# apollo3 register map
Vendor: Ambiq Micro; Series: Apollo; File version: 1.0
CPU: CM4 r1p0, little endian, MPU, FPU, 3 interrupt priority bits
Registers are 32-bit, read-write, reset 0x0 unless marked. A register's access mark holds for its fields unless they carry their own. Offsets are from the block's base; [hi:lo] are bit positions; lines under a group give offsets from that group; {n}, {i} and the like mark numbered series; 'fields as' and 'values as' point back to an identical list.

## GPIO — General Purpose IO
Base 0x40010000
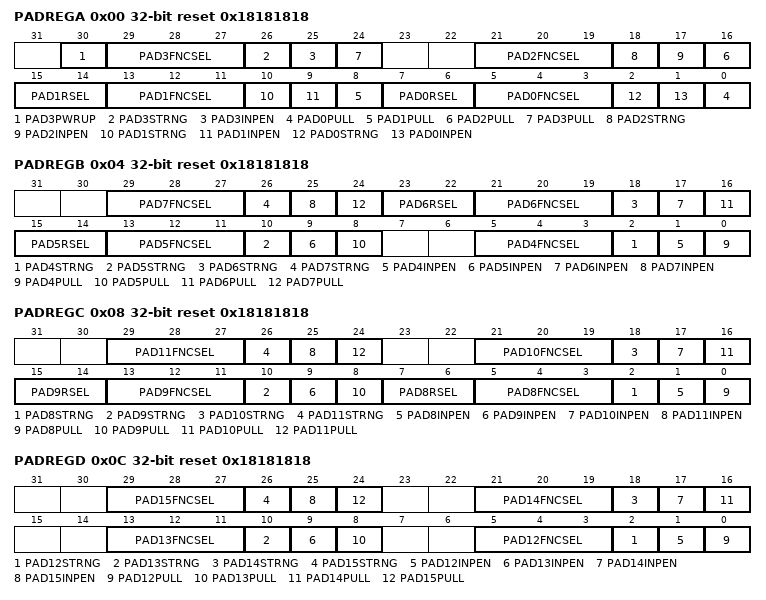
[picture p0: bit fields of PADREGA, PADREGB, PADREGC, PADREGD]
0x00 PADREGA reset 0x18181818 — This register controls the pad configuration controls for PAD3 through PAD0. Writes to this register must be unlocked by the PADKEY register.
  [30] PAD3PWRUP — Pad 3 VDD power switch enable
    0=DIS (Power switch disabled); 1=EN (Power switch enabled (switched to VDD))
  [29:27] PAD3FNCSEL — Pad 3 function select
    0=UA0RTS (Configure as the UART0 RTS output); 1=SLnCE (Configure as the IOSLAVE SPI nCE signal); 2=NCE3 (IOM/MSPI nCE group 3); 3=GPIO3 (Configure as GPIO3); 5=MSPI7 (MSPI data connection 7); 6=TRIG1 (Configure as the ADC Trigger 1 signal); 7=I2S_WCLK (Configure as the PDM I2S Word Clock input)
  [26] PAD3STRNG — Pad 3 drive strength.
    0=LOW (Low drive strength); 1=HIGH (High drive strength)
  [25] PAD3INPEN — Pad 3 input enable.
    0=DIS (Pad input disabled); 1=EN (Pad input enabled)
  [8n] PAD{n}PULL (n=0..3) — Pad {n} pullup enable
    0=DIS (Pullup disabled); 1=EN (Pullup enabled)
  [21:19] PAD2FNCSEL — Pad 2 function select
    0=UART1RX (Configure as the UART1 RX input.); 1=SLMISO (Configure as the IOSLAVE SPI MISO signal.); 2=UART0RX (Configure as the UART0 RX input.); 3=GPIO2 (Configure as GPIO2.); 5=MSPI6 (MSPI data connection 6.); 7=NCE2 (IOM/MSPI nCE group 2)
  [18] PAD2STRNG — Pad 2 drive strength
    0=LOW (Low drive strength); 1=HIGH (High drive strength)
  [17] PAD2INPEN — Pad 2 input enable
    0=DIS (Pad input disabled); 1=EN (Pad input enabled)
  [15:14] PAD1RSEL — Pad 1 pullup resistor selection.
    0=PULL1_5K (Pullup is ~1.5 KOhms); 1=PULL6K (Pullup is ~6 KOhms); 2=PULL12K (Pullup is ~12 KOhms); 3=PULL24K (Pullup is ~24 KOhms)
  [13:11] PAD1FNCSEL — Pad 1 function select
    0=SLSDAWIR3 (Configure as the IOSLAVE I2C SDA or SPI WIR3 signal); 1=SLMOSI (Configure as the IOSLAVE SPI MOSI signal); 2=UART0TX (Configure as the UART0 TX output signal); 3=GPIO1 (Configure as GPIO1); 5=MSPI5 (MSPI data connection 5); 7=NCE1 (IOM/MSPI nCE group 1)
  [10] PAD1STRNG — Pad 1 drive strength
    0=LOW (Low drive strength); 1=HIGH (High drive strength)
  [9] PAD1INPEN — Pad 1 input enable
    0=DIS (Pad input disabled); 1=EN (Pad input enabled)
  [7:6] PAD0RSEL — Pad 0 pullup resistor selection.
    values as PAD1RSEL
  [5:3] PAD0FNCSEL — Pad 0 function select
    0=SLSCL (Configure as the IOSLAVE I2C SCL signal); 1=SLSCK (Configure as the IOSLAVE SPI SCK signal); 2=CLKOUT (Configure as the CLKOUT signal); 3=GPIO0 (Configure as GPIO0); 5=MSPI4 (MSPI data connection 4); 7=NCE0 (IOM/MSPI nCE group 0)
  [2] PAD0STRNG — Pad 0 drive strength
    0=LOW (Low drive strength); 1=HIGH (High drive strength)
  [1] PAD0INPEN — Pad 0 input enable
    0=DIS (Pad input disabled); 1=EN (Pad input enabled)
0x04 PADREGB reset 0x18181818 — This register controls the pad configuration controls for PAD7 through PAD4. Writes to this register must be unlocked by the PADKEY register.
  [29:27] PAD7FNCSEL — Pad 7 function select
    0=NCE7 (IOM/MSPI nCE group 7); 1=M0MOSI (Configure as the IOMSTR0 SPI MOSI signal); 2=CLKOUT (Configure as the CLKOUT signal); 3=GPIO7 (Configure as GPIO7); 4=TRIG0 (Configure as the ADC Trigger 0 signal); 5=UART0TX (Configure as the UART0 TX output signal); 7=CT19 (CTIMER connection 19)
  [8n-30] PAD{n}STRNG (n=4..7) — Pad {n} drive strength
    0=LOW (Low drive strength); 1=HIGH (High drive strength)
  [8n-31] PAD{n}INPEN (n=4..7) — Pad {n} input enable
    0=DIS (Pad input disabled); 1=EN (Pad input enabled)
  [8n-32] PAD{n}PULL (n=4..7) — Pad {n} pullup enable
    0=DIS (Pullup disabled); 1=EN (Pullup enabled)
  [23:22] PAD6RSEL — Pad 6 pullup resistor selection.
    values as PADREGA.PAD1RSEL
  [21:19] PAD6FNCSEL — Pad 6 function select
    0=M0SDAWIR3 (Configure as the IOMSTR0 I2C SDA or SPI WIR3 signal); 1=M0MISO (Configure as the IOMSTR0 SPI MISO signal); 2=UA0CTS (Configure as the UART0 CTS input signal); 3=GPIO6 (Configure as GPIO6); 5=CT10 (CTIMER connection 10); 7=I2S_DAT (Configure as the PDM I2S Data output signal)
  [15:14] PAD5RSEL — Pad 5 pullup resistor selection.
    values as PADREGA.PAD1RSEL
  [13:11] PAD5FNCSEL — Pad 5 function select
    0=M0SCL (Configure as the IOMSTR0 I2C SCL signal); 1=M0SCK (Configure as the IOMSTR0 SPI SCK signal); 2=UA0RTS (Configure as the UART0 RTS signal output); 3=GPIO5 (Configure as GPIO5); 5=EXTHFA (Configure as the External HFA input clock); 7=CT8 (CTIMER connection 8)
  [5:3] PAD4FNCSEL — Pad 4 function select
    0=UA0CTS (Configure as the UART0 CTS input signal); 1=SLINT (Configure as the IOSLAVE interrupt out signal); 2=NCE4 (IOM/SPI nCE group 4); 3=GPIO4 (Configure as GPIO4); 5=UART1RX (Configure as the UART1 RX input); 6=CT17 (CTIMER connection 17); 7=MSPI2 (MSPI data connection 2)
0x08 PADREGC reset 0x18181818 — This register controls the pad configuration controls for PAD11 through PAD8. Writes to this register must be unlocked by the PADKEY register.
  [29:27] PAD11FNCSEL — Pad 11 function select
    0=ADCSE2 (Configure as the analog input for ADC single ended input 2); 1=NCE11 (IOM/MSPI nCE group 11); 2=CT31 (CTIMER connection 31); 3=GPIO11 (Configure as GPIO11); 4=SLINT (Configure as the IOSLAVE interrupt out signal); 5=UA1CTS (Configure as the UART1 CTS input signal); 6=UART0RX (Configure as the UART0 RX input signal); 7=PDM_DATA (Configure as the PDM Data input signal)
  [8n-62] PAD{n}STRNG (n=8..11) — Pad {n} drive strength
    0=LOW (Low drive strength); 1=HIGH (High drive strength)
  [8n-63] PAD{n}INPEN (n=8..11) — Pad {n} input enable
    0=DIS (Pad input disabled); 1=EN (Pad input enabled)
  [8n-64] PAD{n}PULL (n=8..11) — Pad {n} pullup enable
    0=DIS (Pullup disabled); 1=EN (Pullup enabled)
  [21:19] PAD10FNCSEL — Pad 10 function select
    0=UART1TX (Configure as the UART1 TX output signal); 1=M1MOSI (Configure as the IOMSTR1 SPI MOSI signal); 2=NCE10 (IOM/MSPI nCE group 10); 3=GPIO10 (Configure as GPIO10); 4=PDMCLK (PDM serial clock out); 5=UA1RTS (Configure as the UART1 RTS output signal)
  [15:14] PAD9RSEL — Pad 9 pullup resistor selection
    values as PADREGA.PAD1RSEL
  [13:11] PAD9FNCSEL — Pad 9 function select
    0=M1SDAWIR3 (Configure as the IOMSTR1 I2C SDA or SPI WIR3 signal); 1=M1MISO (Configure as the IOMSTR1 SPI MISO signal); 2=NCE9 (IOM/MSPI nCE group 9); 3=GPIO9 (Configure as GPIO9); 4=SCCIO (SCARD data I/O connection); 6=UART1RX (Configure as UART1 RX input signal)
  [7:6] PAD8RSEL — Pad 8 pullup resistor selection.
    values as PADREGA.PAD1RSEL
  [5:3] PAD8FNCSEL — Pad 8 function select
    0=M1SCL (Configure as the IOMSTR1 I2C SCL signal); 1=M1SCK (Configure as the IOMSTR1 SPI SCK signal); 2=NCE8 (IOM/MSPI nCE group 8); 3=GPIO8 (Configure as GPIO8); 4=SCCLK (SCARD serial clock output); 6=UART1TX (Configure as the UART1 TX output signal)
0x0C PADREGD reset 0x18181818 — This register controls the pad configuration controls for PAD15 through PAD12. Writes to this register must be unlocked by the PADKEY register.
  [29:27] PAD15FNCSEL — Pad 15 function select
    0=ADCD1N (Configure as the analog ADC differential pair 1 N input signal); 1=NCE15 (IOM/MSPI nCE group 15); 2=UART1RX (Configure as the UART1 RX signal); 3=GPIO15 (Configure as GPIO15); 4=PDMDATA (PDM serial data input); 5=EXTXT (Configure as the external XTAL oscillator input); 6=SWDIO (Configure as an alternate port for the SWDIO I/O signal); 7=SWO (Configure as an SWO (Serial Wire Trace output))
  [8n-94] PAD{n}STRNG (n=12..15) — Pad {n} drive strength
    0=LOW (Low drive strength); 1=HIGH (High drive strength)
  [8n-95] PAD{n}INPEN (n=12..15) — Pad {n} input enable
    0=DIS (Pad input disabled); 1=EN (Pad input enabled)
  [8n-96] PAD{n}PULL (n=12..15) — Pad {n} pullup enable
    0=DIS (Pullup disabled); 1=EN (Pullup enabled)
  [21:19] PAD14FNCSEL — Pad 14 function select
    0=ADCD1P (Configure as the analog ADC differential pair 1 P input signal); 1=NCE14 (IOM/MSPI nCE group 14); 2=UART1TX (Configure as the UART1 TX output signal); 3=GPIO14 (Configure as GPIO14); 4=PDMCLK (PDM serial clock output); 5=EXTHFS (Configure as the External HFRC oscillator input select); 6=SWDCK (Configure as the alternate input for the SWDCK input signal); 7=32kHzXT (Configure as the 32kHz crystal output signal)
  [13:11] PAD13FNCSEL — Pad 13 function select
    0=ADCD0PSE8 (Configure as the ADC Differential pair 0 P, or Single Ended input 8 analog input signal. Determination of the D0P vs SE8 usage is done when the particular channel is selected within the ADC module); 1=NCE13 (IOM/MSPI nCE group 13); 2=CT2 (CTIMER connection 2); 3=GPIO13 (Configure as GPIO13); 4=I2SBCLK (I2C interface bit clock); 5=EXTHFB (Configure as the external HFRC oscillator input); 6=UA0RTS (Configure as the UART0 RTS signal output); 7=UART1RX (Configure as the UART1 RX input signal)
  [5:3] PAD12FNCSEL — Pad 12 function select
    0=ADCD0NSE9 (Configure as the ADC Differential pair 0 N, or Single Ended input 9 analog input signal. Determination of the D0N vs SE9 usage is done when the particular channel is selected within the ADC module); 1=NCE12 (IOM/MSPI nCE group 12); 2=CT0 (CTIMER connection 0); 3=GPIO12 (Configure as GPIO12); 5=PDMCLK (PDM serial clock output); 6=UA0CTS (Configure as the UART0 CTS input signal); 7=UART1TX (Configure as the UART1 TX output signal)
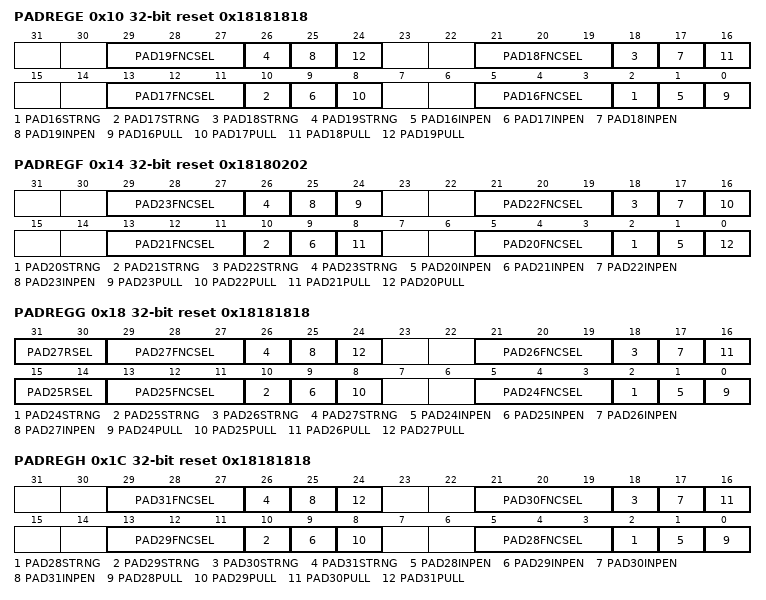
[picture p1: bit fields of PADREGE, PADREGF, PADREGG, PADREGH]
0x10 PADREGE reset 0x18181818 — This register controls the pad configuration controls for PAD19 through PAD16. Writes to this register must be unlocked by the PADKEY register.
  [29:27] PAD19FNCSEL — Pad 19 function select
    0=CMPRF0 (Configure as the analog comparator reference 0 signal); 1=NCE19 (IOM/MSPI nCE group 19); 2=CT6 (CTIMER conenction 6); 3=GPIO19 (Configure as GPIO19); 4=SCCLK (SCARD serial clock); 5=ANATEST1 (Configure as the ANATEST1 I/O signal); 6=UART1RX (Configure as the UART1 RX input signal); 7=I2SBCLK (Configure as the PDM I2S bit clock input signal)
  [8n-126] PAD{n}STRNG (n=16..19) — Pad {n} drive strength
    0=LOW (Low drive strength); 1=HIGH (High drive strength)
  [8n-127] PAD{n}INPEN (n=16..19) — Pad {n} input enable
    0=DIS (Pad input disabled); 1=EN (Pad input enabled)
  [8n-128] PAD{n}PULL (n=16..19) — Pad {n} pullup enable
    0=DIS (Pullup disabled); 1=EN (Pullup enabled)
  [21:19] PAD18FNCSEL — Pad 18 function select
    0=CMPIN1 (Configure as the analog comparator input 1 signal); 1=NCE18 (IOM/MSPI nCE group 18); 2=CT4 (CTIMER connection 4); 3=GPIO18 (Configure as GPIO18); 4=UA0RTS (Configure as UART0 RTS output signal); 5=ANATEST2 (Configure as ANATEST2 I/O signal); 6=UART1TX (Configure as UART1 TX output signal); 7=SCCIO (SCARD data input/output connectin)
  [13:11] PAD17FNCSEL — Pad 17 function select
    0=CMPRF1 (Configure as the analog comparator reference signal 1 input signal); 1=NCE17 (IOM/MSPI nCE group 17); 2=TRIG1 (Configure as the ADC Trigger 1 signal); 3=GPIO17 (Configure as GPIO17); 4=SCCCLK (SCARD serial clock output); 6=UART0RX (Configure as UART0 RX input signal); 7=UA1CTS (Configure as UART1 CTS input signal)
  [5:3] PAD16FNCSEL — Pad 16 function select
    0=ADCSE0 (Configure as the analog ADC single ended port 0 input signal); 1=NCE16 (IOM/MSPI nCE group 16); 2=TRIG0 (Configure as the ADC Trigger 0 signal); 3=GPIO16 (Configure as GPIO16); 4=SCCRST (SCARD reset output); 5=CMPIN0 (Configure as comparator input 0 signal); 6=UART0TX (Configure as UART0 TX output signal); 7=UA1RTS (Configure as UART1 RTS output signal)
0x14 PADREGF reset 0x18180202 — This register controls the pad configuration controls for PAD23 through PAD20. Writes to this register must be unlocked by the PADKEY register.
  [29:27] PAD23FNCSEL — Pad 23 function select
    0=UART0RX (Configure as the UART0 RX signal); 1=NCE23 (IOM/MSPI nCE group 23); 2=CT14 (CTIMER connection 14); 3=GPIO23 (Configure as GPIO23); 4=I2SWCLK (I2S word clock input); 5=CMPOUT (Configure as voltage comparitor output); 6=MSPI3 (MSPI data connection 3); 7=EXTXT (External XTAL osacillatgor input)
  [8n-158] PAD{n}STRNG (n=20..23) — Pad {n} drive strength
    0=LOW (Low drive strength); 1=HIGH (High drive strength)
  [8n-159] PAD{n}INPEN (n=20..23) — Pad {n} input enable
    0=DIS (Pad input disabled); 1=EN (Pad input enabled)
  [24] PAD23PULL — Pad 23 pullup enable
    0=DIS (Pullup disabled); 1=EN (Pullup enabled)
  [21:19] PAD22FNCSEL — Pad 22 function select
    0=UART0TX (Configure as the UART0 TX signal); 1=NCE22 (IOM/MSPI nCE group 22); 2=CT12 (CTIMER connection 12); 3=GPIO22 (Configure as GPIO22); 4=PDM_CLK (Configure as the PDM CLK output); 5=EXTLF (External LFRC input); 6=MSPI0 (MSPI data connection 0); 7=SWO (Configure as the serial trace data output signal)
  [16] PAD22PULL — Pad 22 pullup enable
    0=DIS (Pullup disabled); 1=EN (Pullup enabled)
  [13:11] PAD21FNCSEL — Pad 21 function select
    0=SWDIO (Configure as the serial wire debug data signal); 1=NCE21 (IOM/MSPI nCE group 21); 3=GPIO21 (Configure as GPIO21); 4=UART0RX (Configure as UART0 RX input signal); 5=UART1RX (Configure as UART1 RX input signal); 6=I2SBCLK (I2S byte clock input); 7=UA1CTS (Configure as UART1 CTS input signal)
  [8] PAD21PULL — Pad 21 pullup enable
    0=DIS (Pullup disabled); 1=EN (Pullup enabled)
  [5:3] PAD20FNCSEL — Pad 20 function select
    0=SWDCK (Configure as the serial wire debug clock signal); 1=NCE20 (IOM/MSPI nCE group 20); 3=GPIO20 (Configure as GPIO20); 4=UART0TX (Configure as UART0 TX output signal); 5=UART1TX (Configure as UART1 TX output signal); 6=I2SBCLK (I2S byte clock input); 7=UA1RTS (Configure as UART1 RTS output signal)
  [0] PAD20PULL — Pad 20 pulldown enable
    0=DIS (Pulldown disabled); 1=EN (Pulldown enabled)
0x18 PADREGG reset 0x18181818 — This register controls the pad configuration controls for PAD27 through PAD24. Writes to this register must be unlocked by the PADKEY register.
  [31:30] PAD27RSEL — Pad 27 pullup resistor selection.
    values as PADREGA.PAD1RSEL
  [29:27] PAD27FNCSEL — Pad 27 function select
    0=UART0RX (Configure as UART0 RX input signal); 1=NCE27 (IOM/MSPI nCE group 27); 2=CT5 (CTIMER connection 5); 3=GPIO27 (Configure as GPIO27); 4=M2SCL (Configure as I2C clock I/O signal from IOMSTR2); 5=M2SCK (Configure as SPI clock output signal from IOMSTR2)
  [8n-190] PAD{n}STRNG (n=24..27) — Pad {n} drive strength
    0=LOW (Low drive strength); 1=HIGH (High drive strength)
  [8n-191] PAD{n}INPEN (n=24..27) — Pad {n} input enable
    0=DIS (Pad input disabled); 1=EN (Pad input enabled)
  [8n-192] PAD{n}PULL (n=24..27) — Pad {n} pullup enable
    0=DIS (Pullup disabled); 1=EN (Pullup enabled)
  [21:19] PAD26FNCSEL — Pad 26 function select
    0=EXTHF (Configure as the external HFRC oscillator input); 1=NCE26 (IOM/MSPI nCE group 26); 2=CT3 (CTIMER connection 3); 3=GPIO26 (Configure as GPIO26); 4=SCCRST (SCARD reset output); 5=MSPI1 (MSPI data connection 1); 6=UART0TX (Configure as UART0 TX output signal); 7=UA1CTS (Configure as UART1 CTS input signal)
  [15:14] PAD25RSEL — Pad 25 pullup resistor selection.
    values as PADREGA.PAD1RSEL
  [13:11] PAD25FNCSEL — Pad 25 function select
    0=UART1RX (Configure as UART1 RX input signal); 1=NCE25 (IOM/MSPI nCE group 25); 2=CT1 (CTIMER connection 1); 3=GPIO25 (Configure as GPIO25); 4=M2SDAWIR3 (Configure as the IOMSTR2 I2C SDA or SPI WIR3 signal); 5=M2MISO (Configure as the IOMSTR2 SPI MISO input signal)
  [5:3] PAD24FNCSEL — Pad 24 function select
    0=UART1TX (Configure as UART1 TX output signal); 1=NCE24 (IOM/MSPI nCE group 24); 2=MSPI8 (MSPI data connection 8); 3=GPIO24 (Configure as GPIO24); 4=UA0CTS (Configure as UART0 CTS input signal); 5=CT21 (CTIMER connection 21); 6=32kHzXT (Configure as the 32kHz crystal output signal); 7=SWO (Configure as the serial trace data output signal)
0x1C PADREGH reset 0x18181818 — This register controls the pad configuration controls for PAD31 through PAD28. Writes to this register must be unlocked by the PADKEY register.
  [29:27] PAD31FNCSEL — Pad 31 function select
    0=ADCSE3 (Configure as the analog input for ADC single ended input 3); 1=NCE31 (IOM/MSPI nCE group 31); 2=CT13 (CTIMER connection 13); 3=GPIO31 (Configure as GPIO31); 4=UART0RX (Configure as the UART0 RX input signal); 5=SCCCLK (SCARD serial clock output); 7=UA1RTS (Configure as UART1 RTS output signal)
  [8n-222] PAD{n}STRNG (n=28..31) — Pad {n} drive strength
    0=LOW (Low drive strength); 1=HIGH (High drive strength)
  [8n-223] PAD{n}INPEN (n=28..31) — Pad {n} input enable
    0=DIS (Pad input disabled); 1=EN (Pad input enabled)
  [8n-224] PAD{n}PULL (n=28..31) — Pad {n} pullup enable
    0=DIS (Pullup disabled); 1=EN (Pullup enabled)
  [21:19] PAD30FNCSEL — Pad 30 function select
    0=ANATEST1 (Configure as the ANATEST1 I/O signal); 1=NCE30 (IOM/MSPI nCE group 30); 2=CT11 (CTIMER connection 11); 3=GPIO30 (Configure as GPIO30); 4=UART0TX (Configure as UART0 TX output signal); 5=UA1RTS (Configure as UART1 RTS output signal); 7=I2S_DAT (Configure as the PDM I2S Data output signal)
  [13:11] PAD29FNCSEL — Pad 29 function select
    0=ADCSE1 (Configure as the analog input for ADC single ended input 1); 1=NCE29 (IOM/MSPI nCE group 29); 2=CT9 (CTIMER connection 9); 3=GPIO29 (Configure as GPIO29); 4=UA0CTS (Configure as the UART0 CTS input signal); 5=UA1CTS (Configure as the UART1 CTS input signal); 6=UART0RX (Configure as the UART0 RX input signal); 7=PDM_DATA (Configure as PDM DATA input)
  [5:3] PAD28FNCSEL — Pad 28 function select
    0=I2S_WCLK (Configure as the PDM I2S Word Clock input); 1=NCE28 (IOM/MSPI nCE group 28); 2=CT7 (CTIMER connection 7); 3=GPIO28 (Configure as GPIO28); 5=M2MOSI (Configure as the IOMSTR2 SPI MOSI output signal); 6=UART0TX (Configure as the UART0 TX output signal)
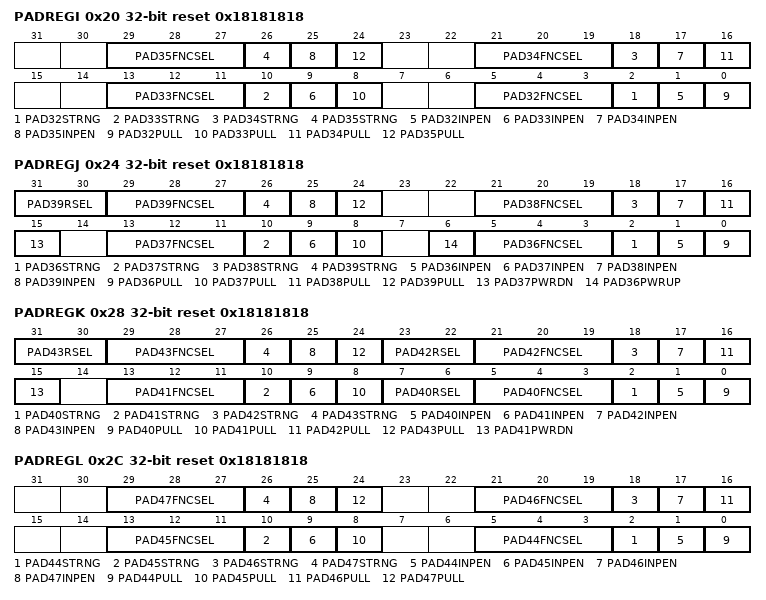
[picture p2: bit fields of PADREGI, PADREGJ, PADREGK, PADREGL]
0x20 PADREGI reset 0x18181818 — This register controls the pad configuration controls for PAD35 through PAD32. Writes to this register must be unlocked by the PADKEY register.
  [29:27] PAD35FNCSEL — Pad 35 function select
    0=ADCSE7 (Configure as the analog input for ADC single ended input 7); 1=NCE35 (IOM/MSPI nCE group 35); 2=UART1TX (Configure as the UART1 TX signal); 3=GPIO35 (Configure as GPIO35); 4=I2SDAT (I2S serial data output); 5=CT27 (CTIMER connection 27); 6=UA0RTS (Configure as the UART0 RTS output)
  [8n-254] PAD{n}STRNG (n=32..35) — Pad {n} drive strength
    0=LOW (Low drive strength); 1=HIGH (High drive strength)
  [8n-255] PAD{n}INPEN (n=32..35) — Pad {n} input enable
    0=DIS (Pad input disabled); 1=EN (Pad input enabled)
  [8n-256] PAD{n}PULL (n=32..35) — Pad {n} pullup enable
    0=DIS (Pullup disabled); 1=EN (Pullup enabled)
  [21:19] PAD34FNCSEL — Pad 34 function select
    0=ADCSE6 (Configure as the analog input for ADC single ended input 6); 1=NCE34 (IOM/MSPI nCE group 34); 2=UA1RTS (Configure as the UART1 RTS output); 3=GPIO34 (Configure as GPIO34); 4=CMPRF2 (Configure as the analog comparator reference 2 signal); 5=UA0RTS (Configure as the UART0 RTS output); 6=UART0RX (Configure as the UART0 RX input); 7=PDMDATA (PDM serial data input)
  [13:11] PAD33FNCSEL — Pad 33 function select
    0=ADCSE5 (Configure as the analog ADC single ended port 5 input signal); 1=NCE33 (IOM/MSPI nCE group 33); 2=32kHzXT (Configure as the 32kHz crystal output signal); 3=GPIO33 (Configure as GPIO33); 5=UA0CTS (Configure as the UART0 CTS input); 6=CT23 (CTIMER connection 23); 7=SWO (Configure as the serial trace data output signal)
  [5:3] PAD32FNCSEL — Pad 32 function select
    0=ADCSE4 (Configure as the analog input for ADC single ended input 4); 1=NCE32 (IOM/MSPI nCE group 32); 2=CT15 (CTIMER connection 15); 3=GPIO32 (Configure as GPIO32); 4=SCCIO (SCARD serial data input/output); 5=EXTLF (External input to the LFRC oscillator); 7=UA1CTS (Configure as the UART1 CTS input)
0x24 PADREGJ reset 0x18181818 — This register controls the pad configuration controls for PAD39 through PAD36. Writes to this register must be unlocked by the PADKEY register.
  [31:30] PAD39RSEL — Pad 39 pullup resistor selection.
    values as PADREGA.PAD1RSEL
  [29:27] PAD39FNCSEL — Pad 39 function select
    0=UART0TX (Configure as the UART0 TX output signal); 1=UART1TX (Configure as the UART1 TX output signal); 2=CT25 (CTIMER connection 25); 3=GPIO39 (Configure as GPIO39); 4=M4SCL (Configure as the IOMSTR4 I2C SCL signal); 5=M4SCK (Configure as the IOMSTR4 SPI SCK signal)
  [8n-286] PAD{n}STRNG (n=36..39) — Pad {n} drive strength
    0=LOW (Low drive strength); 1=HIGH (High drive strength)
  [8n-287] PAD{n}INPEN (n=36..39) — Pad {n} input enable
    0=DIS (Pad input disabled); 1=EN (Pad input enabled)
  [8n-288] PAD{n}PULL (n=36..39) — Pad {n} pullup enable
    0=DIS (Pullup disabled); 1=EN (Pullup enabled)
  [21:19] PAD38FNCSEL — Pad 38 function select
    0=TRIG3 (Configure as the ADC Trigger 3 signal); 1=NCE38 (IOM/MSPI nCE group 38); 2=UA0CTS (Configure as the UART0 CTS signal); 3=GPIO38 (Configure as GPIO38); 5=M3MOSI (Configure as the IOMSTR3 SPI MOSI output signal); 6=UART1RX (Configure as the UART1 RX input signal)
  [15] PAD37PWRDN — Pad 37 VSS power switch enable
    0=DIS (Power switch disabled); 1=EN (Power switch enabled (switch to GND))
  [13:11] PAD37FNCSEL — Pad 37 function select
    0=TRIG2 (Configure as the ADC Trigger 2 signal); 1=NCE37 (IOM/MSPI nCE group 37); 2=UA0RTS (Configure as the UART0 RTS output signal); 3=GPIO37 (Configure as GPIO37); 4=SCCIO (SCARD serial data input/output); 5=UART1TX (Configure as the UART1 TX output signal); 6=PDMCLK (Configure as the PDM CLK output signal); 7=CT29 (CTIMER connection 29)
  [6] PAD36PWRUP — Pad 36 VDD power switch enable
    values as PADREGA.PAD3PWRUP
  [5:3] PAD36FNCSEL — Pad 36 function select
    0=TRIG1 (Configure as the ADC Trigger 1 signal); 1=NCE36 (IOM/MSPI nCE group 36); 2=UART1RX (Configure as the UART1 RX input signal); 3=GPIO36 (Configure as GPIO36); 4=32kHzXT (Configure as the 32kHz output clock from the crystal); 5=UA1CTS (Configure as the UART1 CTS input signal); 6=UA0CTS (Configure as the UART0 CTS input signal); 7=PDMDATA (PDM serial data input)
0x28 PADREGK reset 0x18181818 — This register controls the pad configuration controls for PAD43 through PAD40. Writes to this register must be unlocked by the PADKEY register.
  [31:30] PAD43RSEL — Pad 43 pullup resistor selection.
    values as PADREGA.PAD1RSEL
  [29:27] PAD43FNCSEL — Pad 43 function select
    0=UART1RX (Configure as the UART1 RX input signal); 1=NCE43 (IOM/MSPI nCE group 43); 2=CT18 (CTIMER connection 18); 3=GPIO43 (Configure as GPIO43); 4=M3SDAWIR3 (Configure as the IOMSTR3 I2C SDA or SPI WIR3 signal); 5=M3MISO (Configure as the IOMSTR3 SPI MISO signal)
  [8n-318] PAD{n}STRNG (n=40..43) — Pad {n} drive strength
    0=LOW (Low drive strength); 1=HIGH (High drive strength)
  [8n-319] PAD{n}INPEN (n=40..43) — Pad {n} input enable
    0=DIS (Pad input disabled); 1=EN (Pad input enabled)
  [8n-320] PAD{n}PULL (n=40..43) — Pad {n} pullup enable
    0=DIS (Pullup disabled); 1=EN (Pullup enabled)
  [23:22] PAD42RSEL — Pad 42 pullup resistor selection.
    values as PADREGA.PAD1RSEL
  [21:19] PAD42FNCSEL — Pad 42 function select
    0=UART1TX (Configure as the UART1 TX output signal); 1=NCE42 (IOM/MSPI nCE group 42); 2=CT16 (CTIMER connection 16); 3=GPIO42 (Configure as GPIO42); 4=M3SCL (Configure as the IOMSTR3 I2C SCL clock I/O signal); 5=M3SCK (Configure as the IOMSTR3 SPI SCK output)
  [15] PAD41PWRDN — Pad 41 power switch enable
    0=DIS (Power switch disabled); 1=EN (Power switch enabled (Switch pad to VSS))
  [13:11] PAD41FNCSEL — Pad 41 function select
    0=NCE41 (IOM/MSPI nCE group 41); 2=SWO (Configure as the serial wire debug SWO signal); 3=GPIO41 (Configure as GPIO41); 4=I2SWCLK (I2S word clock input); 5=UA1RTS (Configure as the UART1 RTS output signal); 6=UART0TX (Configure as the UART0 TX output signal); 7=UA0RTS (Configure as the UART0 RTS output signal)
  [7:6] PAD40RSEL — Pad 40 pullup resistor selection.
    values as PADREGA.PAD1RSEL
  [5:3] PAD40FNCSEL — Pad 40 function select
    0=UART0RX (Configure as the UART0 RX input signal); 1=UART1RX (Configure as the UART1 RX input signal); 2=TRIG0 (Configure as the ADC Trigger 0 signal); 3=GPIO40 (Configure as GPIO40); 4=M4SDAWIR3 (Configure as the IOMSTR4 I2C SDA or SPI WIR3 signal); 5=M4MISO (Configure as the IOMSTR4 SPI MISO input signal)
0x2C PADREGL reset 0x18181818 — This register controls the pad configuration controls for PAD47 through PAD44. Writes to this register must be unlocked by the PADKEY register.
  [29:27] PAD47FNCSEL — Pad 47 function select
    0=32kHzXT (Configure as the 32kHz output clock from the crystal); 1=NCE47 (IOM/MSPI nCE group 47); 2=CT26 (CTIMER connection 26); 3=GPIO47 (Configure as GPIO47); 5=M5MOSI (Configure as the IOMSTR5 SPI MOSI output signal); 6=UART1RX (Configure as the UART1 RX input signal)
  [8n-350] PAD{n}STRNG (n=44..47) — Pad {n} drive strength
    0=LOW (Low drive strength); 1=HIGH (High drive strength)
  [8n-351] PAD{n}INPEN (n=44..47) — Pad {n} input enable
    0=DIS (Pad input disabled); 1=EN (Pad input enabled)
  [8n-352] PAD{n}PULL (n=44..47) — Pad {n} pullup enable
    0=DIS (Pullup disabled); 1=EN (Pullup enabled)
  [21:19] PAD46FNCSEL — Pad 46 function select
    0=32khz_XT (Configure as the 32kHz output clock from the crystal); 1=NCE46 (IOM/MSPI nCE group 46); 2=CT24 (CTIMER connection 24); 3=GPIO46 (Configure as GPIO46); 4=SCCRST (SCARD reset output); 5=PDMCLK (PDM serial clock output); 6=UART1TX (Configure as the UART1 TX output signal); 7=SWO (Configure as the serial wire debug SWO signal)
  [13:11] PAD45FNCSEL — Pad 45 function select
    0=UA1CTS (Configure as the UART1 CTS input signal); 1=NCE45 (IOM/MSPI nCE group 45); 2=CT22 (CTIMER connection 22); 3=GPIO45 (Configure as GPIO45); 4=I2SDAT (I2S serial data output); 5=PDMDATA (PDM serial data input); 6=UART0RX (Configure as the SPI channel 5 nCE signal from IOMSTR5); 7=SWO (Configure as the serial wire debug SWO signal)
  [5:3] PAD44FNCSEL — Pad 44 function select
    0=UA1RTS (Configure as the UART1 RTS output signal); 1=NCE44 (IOM/MSPI nCE group 44); 2=CT20 (CTIMER connection 20); 3=GPIO44 (Configure as GPIO44); 5=M4MOSI (Configure as the IOMSTR4 SPI MOSI signal); 6=UART0TX (Configure as the UART0 TX output signal)
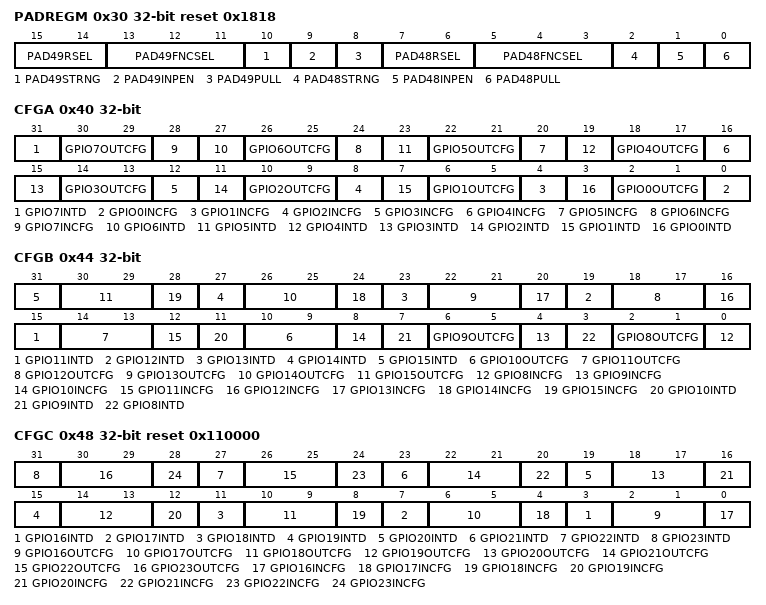
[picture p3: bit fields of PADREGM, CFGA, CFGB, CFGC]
0x30 PADREGM reset 0x1818 — This register controls the pad configuration controls for PAD49 through PAD48. Writes to this register must be unlocked by the PADKEY register.
  [15:14] PAD49RSEL — Pad 49 pullup resistor selection.
    values as PADREGA.PAD1RSEL
  [13:11] PAD49FNCSEL — Pad 49 function select
    0=UART0RX (Configure as the UART0 RX input signal); 1=NCE49 (IOM/MSPPI nCE group 49); 2=CT30 (CTIMER connection 30); 3=GPIO49 (Configure as GPIO49); 4=M5SDAWIR3 (Configure as the IOMSTR5 I2C SDA or SPI WIR3 signal); 5=M5MISO (Configure as the IOMSTR5 SPI MISO input signal)
  [10] PAD49STRNG — Pad 49 drive strength
    0=LOW (Low drive strength); 1=HIGH (High drive strength)
  [9] PAD49INPEN — Pad 49 input enable
    0=DIS (Pad input disabled); 1=EN (Pad input enabled)
  [8] PAD49PULL — Pad 49 pullup enable
    0=DIS (Pullup disabled); 1=EN (Pullup enabled)
  [7:6] PAD48RSEL — Pad 48 pullup resistor selection.
    values as PADREGA.PAD1RSEL
  [5:3] PAD48FNCSEL — Pad 48 function select
    0=UART0TX (Configure as the UART0 TX output signal); 1=NCE48 (IOM/MSPI nCE group 48); 2=CT28 (CTIMER conenction 28); 3=GPIO48 (Configure as GPIO48); 4=M5SCL (Configure as the IOMSTR5 I2C SCL clock I/O signal); 5=M5SCK (Configure as the IOMSTR5 SPI SCK output)
  [2] PAD48STRNG — Pad 48 drive strength
    0=LOW (Low drive strength); 1=HIGH (High drive strength)
  [1] PAD48INPEN — Pad 48 input enable
    0=DIS (Pad input disabled); 1=EN (Pad input enabled)
  [0] PAD48PULL — Pad 48 pullup enable
    0=DIS (Pullup disabled); 1=EN (Pullup enabled)
0x40 CFGA — GPIO configuration controls for GPIO[7:0]. Writes to this register must be unlocked by the PADKEY register.
  [31] GPIO7INTD — GPIO7 interrupt direction, nCE polarity.
    0=nCELOW (FNCSEL = 0x0 - nCE polarity active low); 1=nCEHIGH (FNCSEL = 0x0 - nCE polarity active high)
  [4n+2:4n+1] GPIO{n}OUTCFG (n=0..7) — GPIO{n} output configuration.
    0=DIS (FNCSEL = 0x3 - Output disabled); 1=PUSHPULL (FNCSEL = 0x3 - Output is push-pull); 2=OD (FNCSEL = 0x3 - Output is open drain); 3=TS (FNCSEL = 0x3 - Output is tri-state)
  [4n] GPIO{n}INCFG (n=0..7) — GPIO{n} input enable.
    0=READ (Read the GPIO pin data); 1=RDZERO (INTD = 0 - Readback will always be zero)
  [27] GPIO6INTD — GPIO6 interrupt direction.
    0=INTDIS (INCFG = 1 - No interrupt on GPIO transition); 1=INTBOTH (INCFG = 1 - Interrupt on either low to high or high to low GPIO transition)
  [23] GPIO5INTD — GPIO5 interrupt direction.
    values as GPIO6INTD
  [19] GPIO4INTD — GPIO4 interrupt direction.
    0=nCELOW (FNCSEL = 0x2 - nCE polarity active low); 1=nCEHIGH (FNCSEL = 0x2 - nCE polarity active high)
  [15] GPIO3INTD — GPIO3 interrupt direction.
    values as GPIO4INTD
  [11] GPIO2INTD — GPIO2 interrupt direction.
    0=nCELOW (FNCSEL = 0x7 - nCE polarity active low); 1=nCEHIGH (FNCSEL = 0x7 - nCE polarity active high)
  [7] GPIO1INTD — GPIO1 interrupt direction.
    values as GPIO2INTD
  [3] GPIO0INTD — GPIO0 interrupt direction.
    values as GPIO2INTD
0x44 CFGB — GPIO configuration controls for GPIO[15:8]. Writes to this register must be unlocked by the PADKEY register.
  [4n-29] GPIO{n}INTD (n=11..15) — GPIO{n} interrupt direction.
    0=nCELOW (FNCSEL = 0x1 - nCE polarity active low); 1=nCEHIGH (FNCSEL = 0x1 - nCE polarity active high)
  [4n-30:4n-31] GPIO{n}OUTCFG (n=8..15) — GPIO{n} output configuration.
    values as CFGA.GPIO0OUTCFG
  [4n-32] GPIO{n}INCFG (n=8..15) — GPIO{n} input enable.
    values as CFGA.GPIO0INCFG
  [11] GPIO10INTD — GPIO10 interrupt direction.
    values as CFGA.GPIO4INTD
  [7] GPIO9INTD — GPIO9 interrupt direction.
    values as CFGA.GPIO4INTD
  [3] GPIO8INTD — GPIO8 interrupt direction.
    values as CFGA.GPIO4INTD
0x48 CFGC reset 0x110000 — GPIO configuration controls for GPIO[23:16]. Writes to this register must be unlocked by the PADKEY register.
  [4n-61] GPIO{n}INTD (n=16..23) — GPIO{n} interrupt direction.
    values as CFGB.GPIO11INTD
  [4n-62:4n-63] GPIO{n}OUTCFG (n=16..23) — GPIO{n} output configuration.
    values as CFGA.GPIO0OUTCFG
  [4n-64] GPIO{n}INCFG (n=16..23) — GPIO{n} input enable.
    values as CFGA.GPIO0INCFG
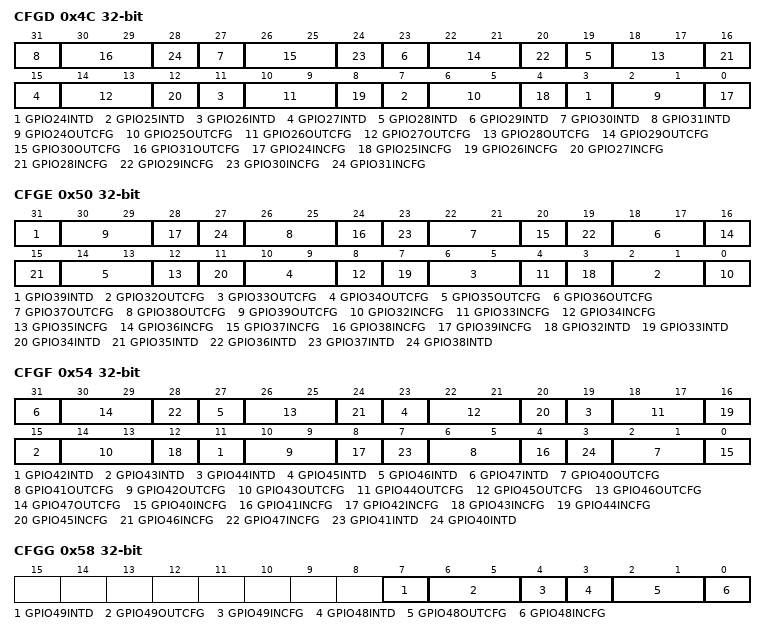
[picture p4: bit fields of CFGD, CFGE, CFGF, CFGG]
0x4C CFGD — GPIO configuration controls for GPIO[31:24]. Writes to this register must be unlocked by the PADKEY register.
  [4n-93] GPIO{n}INTD (n=24..31) — GPIO{n} interrupt direction.
    values as CFGB.GPIO11INTD
  [4n-94:4n-95] GPIO{n}OUTCFG (n=24..31) — GPIO{n} output configuration.
    values as CFGA.GPIO0OUTCFG
  [4n-96] GPIO{n}INCFG (n=24..31) — GPIO{n} input enable.
    values as CFGA.GPIO0INCFG
0x50 CFGE — GPIO configuration controls for GPIO[39:32]. Writes to this register must be unlocked by the PADKEY register.
  [31] GPIO39INTD — GPIO39 interrupt direction.
    values as CFGA.GPIO6INTD
  [4n-126:4n-127] GPIO{n}OUTCFG (n=32..39) — GPIO{n} output configuration.
    values as CFGA.GPIO0OUTCFG
  [4n-128] GPIO{n}INCFG (n=32..39) — GPIO{n} input enable.
    values as CFGA.GPIO0INCFG
  [4n-125] GPIO{n}INTD (n=32..38) — GPIO{n} interrupt direction.
    values as CFGB.GPIO11INTD
0x54 CFGF — GPIO configuration controls for GPIO[47:40]. Writes to this register must be unlocked by the PADKEY register.
  [4n-157] GPIO{n}INTD (n=42..47) — GPIO{n} interrupt direction.
    values as CFGB.GPIO11INTD
  [4n-158:4n-159] GPIO{n}OUTCFG (n=40..47) — GPIO{n} output configuration.
    values as CFGA.GPIO0OUTCFG
  [4n-160] GPIO{n}INCFG (n=40..47) — GPIO{n} input enable.
    values as CFGA.GPIO0INCFG
  [7] GPIO41INTD — GPIO41 interrupt direction.
    values as CFGA.GPIO7INTD
  [3] GPIO40INTD — GPIO40 interrupt direction.
    values as CFGA.GPIO6INTD
0x58 CFGG — GPIO configuration controls for GPIO[49:48]. Writes to this register must be unlocked by the PADKEY register.
  [7] GPIO49INTD — GPIO49 interrupt direction.
    values as CFGB.GPIO11INTD
  [6:5] GPIO49OUTCFG — GPIO49 output configuration.
    values as CFGA.GPIO0OUTCFG
  [4] GPIO49INCFG — GPIO49 input enable.
    values as CFGA.GPIO0INCFG
  [3] GPIO48INTD — GPIO48 interrupt direction.
    values as CFGB.GPIO11INTD
  [2:1] GPIO48OUTCFG — GPIO48 output configuration.
    values as CFGA.GPIO0OUTCFG
  [0] GPIO48INCFG — GPIO48 input enable.
    values as CFGA.GPIO0INCFG
0x60 PADKEY — Lock state of the PINCFG and GPIO configuration registers. Write a value of 0x73 to unlock write access to the PAD and GPIO configuration registers. Write any other value to lock access to PAD and GPIO registers. This register also indicates lock status when read. When in the unlccked state (i.e. 0x73 has been written), it reads as 1. When in the locked state, it reads as 0.
  [31:0] PADKEY — Key register value.
    115=Key (Key value to unlock the register.)
0x80 RDA — GPIO Input Register A (31-0)
  [31:0] RDA — GPIO31-0 read data.
0x84 RDB — GPIO Input Register B (49-32)
  [17:0] RDB — GPIO49-32 read data.
0x88 WTA — GPIO Output Register A (31-0)
  [31:0] WTA — GPIO31-0 write data.
0x8C WTB — GPIO Output Register B (49-32)
  [17:0] WTB — GPIO49-32 write data.
0x90 WTSA — GPIO Output Register A Set (31-0)
  [31:0] WTSA — Set the GPIO31-0 write data.
0x94 WTSB — GPIO Output Register B Set (49-32)
  [17:0] WTSB — Set the GPIO49-32 write data.
0x98 WTCA — GPIO Output Register A Clear (31-0)
  [31:0] WTCA — Clear the GPIO31-0 write data.
0x9C WTCB — GPIO Output Register B Clear (49-32)
  [17:0] WTCB — Clear the GPIO49-32 write data.
0xA0 ENA — GPIO Enable Register A (31-0)
  [31:0] ENA — GPIO31-0 output enables
0xA4 ENB — GPIO Enable Register B (49-32)
  [17:0] ENB — GPIO49-32 output enables
0xA8 ENSA — GPIO Enable Register A Set (31-0)
  [31:0] ENSA — Set the GPIO31-0 output enables
0xAC ENSB — GPIO Enable Register B Set (49-32)
  [17:0] ENSB — Set the GPIO49-32 output enables
0xB4 ENCA — GPIO Enable Register A Clear (31-0)
  [31:0] ENCA — Clear the GPIO31-0 output enables
0xB8 ENCB — GPIO Enable Register B Clear (49-32)
  [17:0] ENCB — Clear the GPIO49-32 output enables
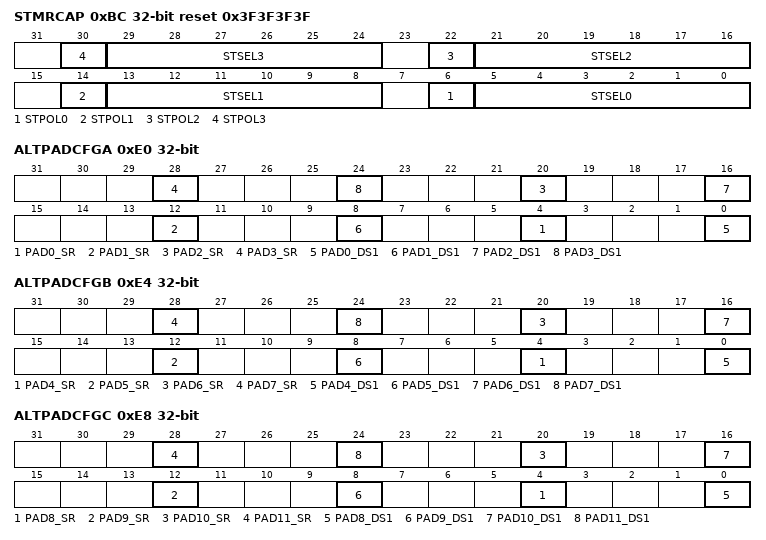
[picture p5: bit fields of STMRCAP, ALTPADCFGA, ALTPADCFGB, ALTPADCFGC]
0xBC STMRCAP reset 0x3F3F3F3F — STIMER Capture trigger select and enable.
  [8n+6] STPOL{n} (n=0..3) — STIMER Capture {n} Polarity.
    0=CAPLH (Capture on low to high GPIO transition); 1=CAPHL (Capture on high to low GPIO transition)
  [8n+5:8n] STSEL{n} (n=0..3) — STIMER Capture {n} Select.
{0xC0+4i} IOM{i}IRQ reset 0x3F (i=0..5) — IOMSTR{i} IRQ select for flow control.
  [5:0] IOM{i}IRQ — IOMSTR{i} IRQ pad select.
0xD8 BLEIFIRQ reset 0x3F — BLE IF IRQ select for flow control.
  [5:0] BLEIFIRQ — BLEIF IRQ pad select.
0xDC GPIOOBS — GPIO Observation mode sample register
  [15:0] OBS_DATA — Sample of the data output on the GPIO observation port. May have async sampling issues, as the data is not synronized to the read operation. Intended for debug purposes only
0xE0 ALTPADCFGA — This register has additional configuration control for pads 3, 2, 1, 0
  [8n+4] PAD{n}_SR (n=0..3) — Pad {n} slew rate selection.
    1=SR_EN (Enables Slew rate control on pad)
  [8n] PAD{n}_DS1 (n=0..3) — Pad {n} high order drive strength selection. Used in conjunction with PAD{n}STRNG field to set the pad drive strength.
0xE4 ALTPADCFGB — This register has additional configuration control for pads 7, 6, 5, 4
  [8n-28] PAD{n}_SR (n=4..7) — Pad {n} slew rate selection.
    1=SR_EN (Enables Slew rate control on pad)
  [8n-32] PAD{n}_DS1 (n=4..7) — Pad {n} high order drive strength selection. Used in conjunction with PAD{n}STRNG field to set the pad drive strength.
0xE8 ALTPADCFGC — This register has additional configuration control for pads 11, 10, 9, 8
  [8n-60] PAD{n}_SR (n=8..11) — Pad {n} slew rate selection.
    1=SR_EN (Enables Slew rate control on pad)
  [8n-64] PAD{n}_DS1 (n=8..11) — Pad {n} high order drive strength selection. Used in conjunction with PAD{n}STRNG field to set the pad drive strength.
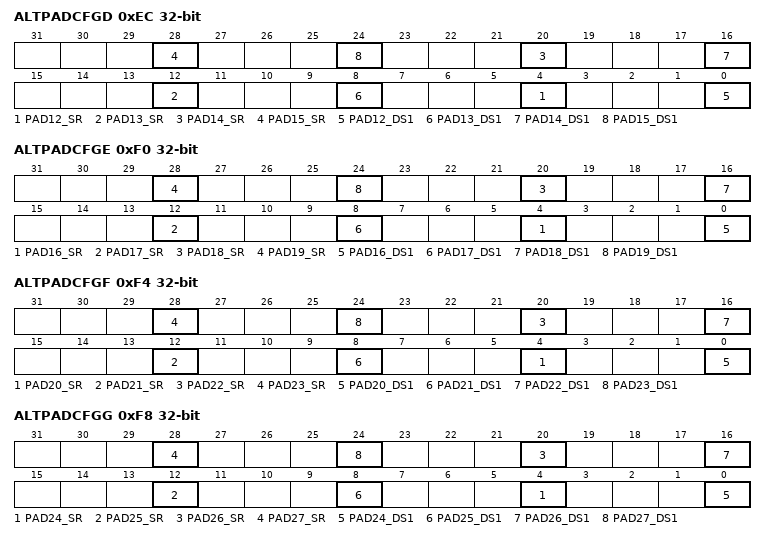
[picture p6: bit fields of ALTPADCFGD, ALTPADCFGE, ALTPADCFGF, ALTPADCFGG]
0xEC ALTPADCFGD — This register has additional configuration control for pads 15, 14, 13, 12
  [8n-92] PAD{n}_SR (n=12..15) — Pad {n} slew rate selection.
    1=SR_EN (Enables Slew rate control on pad)
  [8n-96] PAD{n}_DS1 (n=12..15) — Pad {n} high order drive strength selection. Used in conjunction with PAD{n}STRNG field to set the pad drive strength.
0xF0 ALTPADCFGE — This register has additional configuration control for pads 19, 18, 17, 16
  [8n-124] PAD{n}_SR (n=16..19) — Pad {n} slew rate selection.
    1=SR_EN (Enables Slew rate control on pad)
  [8n-128] PAD{n}_DS1 (n=16..19) — Pad {n} high order drive strength selection. Used in conjunction with PAD{n}STRNG field to set the pad drive strength.
0xF4 ALTPADCFGF — This register has additional configuration control for pads 23, 22, 21, 20
  [8n-156] PAD{n}_SR (n=20..23) — Pad {n} slew rate selection.
    1=SR_EN (Enables Slew rate control on pad)
  [8n-160] PAD{n}_DS1 (n=20..23) — Pad {n} high order drive strength selection. Used in conjunction with PAD{n}STRNG field to set the pad drive strength.
0xF8 ALTPADCFGG — This register has additional configuration control for pads 27, 26, 25, 24
  [8n-188] PAD{n}_SR (n=24..27) — Pad {n} slew rate selection.
    1=SR_EN (Enables Slew rate control on pad)
  [8n-192] PAD{n}_DS1 (n=24..27) — Pad {n} high order drive strength selection. Used in conjunction with PAD{n}STRNG field to set the pad drive strength.
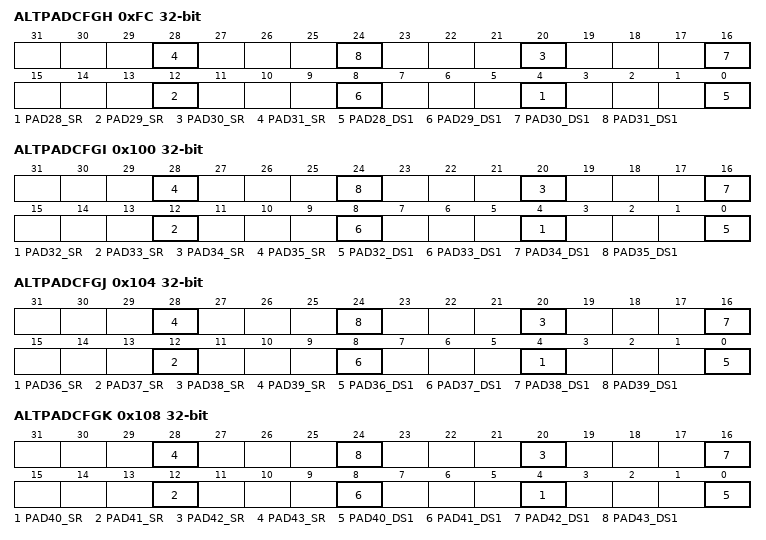
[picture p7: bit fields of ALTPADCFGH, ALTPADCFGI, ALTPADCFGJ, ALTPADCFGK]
0xFC ALTPADCFGH — This register has additional configuration control for pads 31, 30, 29, 28
  [8n-220] PAD{n}_SR (n=28..31) — Pad {n} slew rate selection.
    1=SR_EN (Enables Slew rate control on pad)
  [8n-224] PAD{n}_DS1 (n=28..31) — Pad {n} high order drive strength selection. Used in conjunction with PAD{n}STRNG field to set the pad drive strength.
0x100 ALTPADCFGI — This register has additional configuration control for pads 35, 34, 33, 32
  [8n-252] PAD{n}_SR (n=32..35) — Pad {n} slew rate selection.
    1=SR_EN (Enables Slew rate control on pad)
  [8n-256] PAD{n}_DS1 (n=32..35) — Pad {n} high order drive strength selection. Used in conjunction with PAD{n}STRNG field to set the pad drive strength.
0x104 ALTPADCFGJ — This register has additional configuration control for pads 39, 38, 37, 36
  [8n-284] PAD{n}_SR (n=36..39) — Pad {n} slew rate selection.
    1=SR_EN (Enables Slew rate control on pad)
  [8n-288] PAD{n}_DS1 (n=36..39) — Pad {n} high order drive strength selection. Used in conjunction with PAD{n}STRNG field to set the pad drive strength.
0x108 ALTPADCFGK — This register has additional configuration control for pads 43, 42, 41, 40
  [8n-316] PAD{n}_SR (n=40..43) — Pad {n} slew rate selection.
    1=SR_EN (Enables Slew rate control on pad)
  [8n-320] PAD{n}_DS1 (n=40..43) — Pad {n} high order drive strength selection. Used in conjunction with PAD{n}STRNG field to set the pad drive strength.
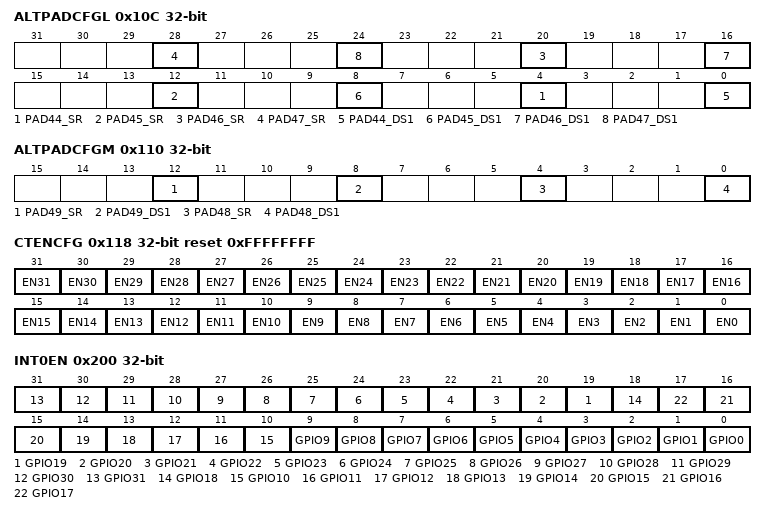
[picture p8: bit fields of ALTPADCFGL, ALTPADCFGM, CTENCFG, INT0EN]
0x10C ALTPADCFGL — This register has additional configuration control for pads 47, 46, 45, 44
  [8n-348] PAD{n}_SR (n=44..47) — Pad {n} slew rate selection.
    1=SR_EN (Enables Slew rate control on pad)
  [8n-352] PAD{n}_DS1 (n=44..47) — Pad {n} high order drive strength selection. Used in conjunction with PAD{n}STRNG field to set the pad drive strength.
0x110 ALTPADCFGM — This register has additional configuration control for pads 49, 48
  [12] PAD49_SR — Pad 49 slew rate selection.
    1=SR_EN (Enables Slew rate control on pad)
  [8] PAD49_DS1 — Pad 49 high order drive strength selection. Used in conjunction with PAD49STRNG field to set the pad drive strength.
  [4] PAD48_SR — Pad 48 slew rate selection.
    1=SR_EN (Enables Slew rate control on pad)
  [0] PAD48_DS1 — Pad 48 high order drive strength selection. Used in conjunction with PAD48STRNG field to set the pad drive strength.
0x114 SCDET reset 0x3F — Scard card detect select.
  [5:0] SCDET — SCARD card detect pad select.
0x118 CTENCFG reset 0xFFFFFFFF — Pad enable configuration.
  [n] EN{n} (n=10..31) — CT{n} Enable
    1=DIS (Disable CT{n} for output); 0=EN (Enable CT{n} for output)
  [9] EN9 — CT9 Enable
    0=DIS (Disable CT9 for output)
  [n] EN{n} (n=0..8) — CT{n} Enable
    values as EN10
0x200 INT0EN — Set bits in this register to allow this module to generate the corresponding interrupt.
  [n] GPIO{n} (n=19..31) — GPIO{n} interrupt.
  [18] GPIO18 — GPIO18interrupt.
  [n] GPIO{n} (n=0..17) — GPIO{n} interrupt.
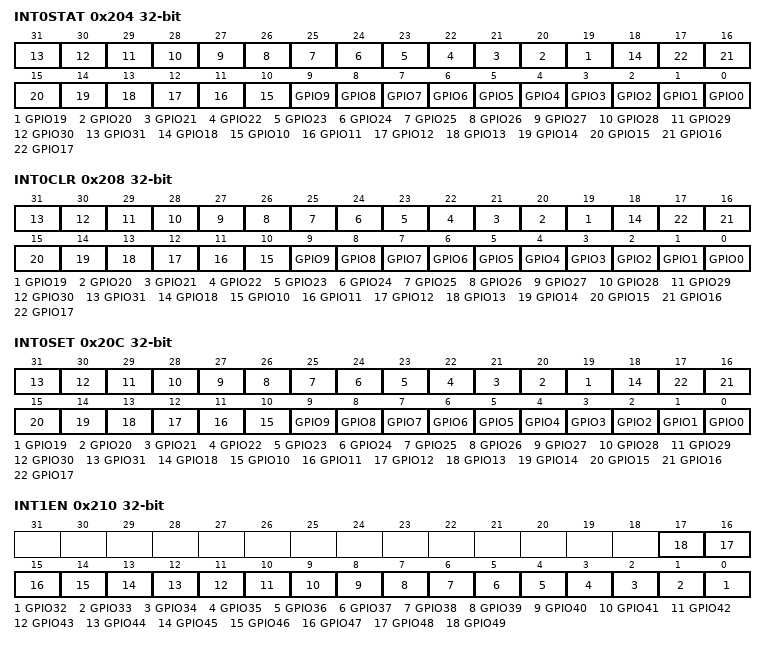
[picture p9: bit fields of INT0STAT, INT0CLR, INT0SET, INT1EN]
0x204 INT0STAT — Read bits from this register to discover the cause of a recent interrupt.
  fields as INT0EN
0x208 INT0CLR — Write a 1 to a bit in this register to clear the interrupt status associated with that bit.
  fields as INT0EN
0x20C INT0SET — Write a 1 to a bit in this register to instantly generate an interrupt from this module. (Generally used for testing purposes).
  fields as INT0EN
0x210 INT1EN — Set bits in this register to allow this module to generate the corresponding interrupt.
  [n-32] GPIO{n} (n=32..49) — GPIO{n} interrupt.
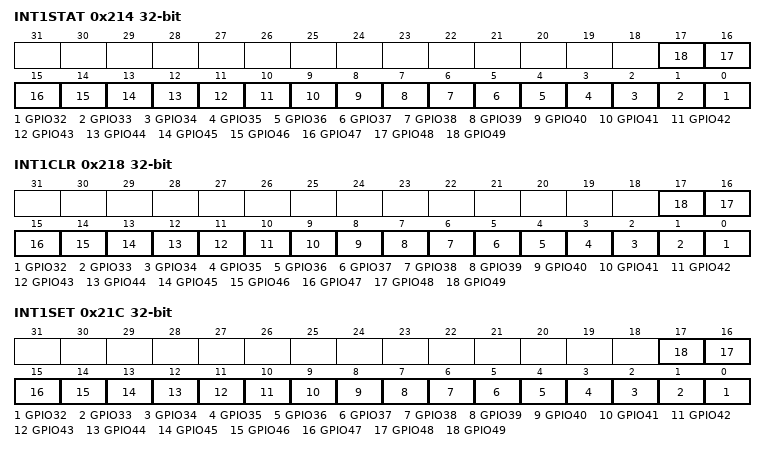
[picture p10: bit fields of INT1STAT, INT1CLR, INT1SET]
0x214 INT1STAT — Read bits from this register to discover the cause of a recent interrupt.
  [n-32] GPIO{n} (n=32..49) — GPIO{n} interrupt.
0x218 INT1CLR — Write a 1 to a bit in this register to clear the interrupt status associated with that bit.
  [n-32] GPIO{n} (n=32..49) — GPIO{n} interrupt.
0x21C INT1SET — Write a 1 to a bit in this register to instantly generate an interrupt from this module. (Generally used for testing purposes).
  [n-32] GPIO{n} (n=32..49) — GPIO{n} interrupt.
